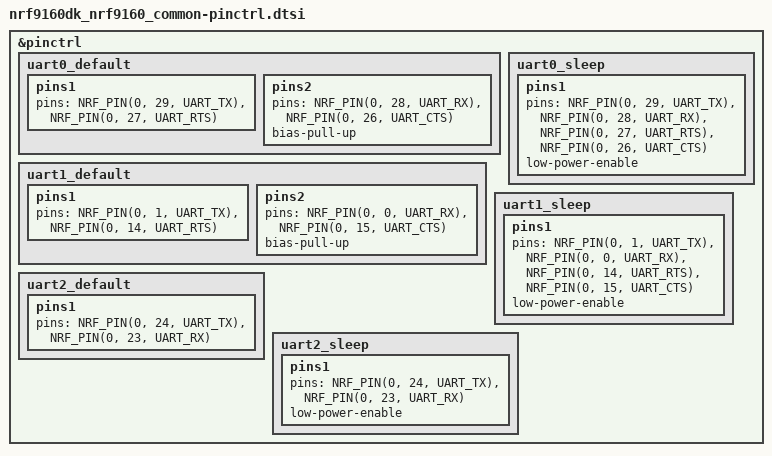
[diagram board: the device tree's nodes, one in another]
/*
 * Copyright (c) 2021 Nordic Semiconductor ASA
 * SPDX-License-Identifier: Apache-2.0
 */

&pinctrl {
	uart0_default: uart0_default {
		pins1 {
			pins = <NRF_PIN(0, 29, UART_TX)>,
			       <NRF_PIN(0, 27, UART_RTS)>;
		};
		pins2 {
			pins = <NRF_PIN(0, 28, UART_RX)>,
			       <NRF_PIN(0, 26, UART_CTS)>;
			bias-pull-up;
		};
	};

	uart0_sleep: uart0_sleep {
		pins1 {
			pins = <NRF_PIN(0, 29, UART_TX)>,
			       <NRF_PIN(0, 28, UART_RX)>,
			       <NRF_PIN(0, 27, UART_RTS)>,
			       <NRF_PIN(0, 26, UART_CTS)>;
			low-power-enable;
		};
	};

	uart1_default: uart1_default {
		pins1 {
			pins = <NRF_PIN(0, 1, UART_TX)>,
			       <NRF_PIN(0, 14, UART_RTS)>;
		};
		pins2 {
			pins = <NRF_PIN(0, 0, UART_RX)>,
			       <NRF_PIN(0, 15, UART_CTS)>;
			bias-pull-up;
		};
	};

	uart1_sleep: uart1_sleep {
		pins1 {
			pins = <NRF_PIN(0, 1, UART_TX)>,
			       <NRF_PIN(0, 0, UART_RX)>,
			       <NRF_PIN(0, 14, UART_RTS)>,
			       <NRF_PIN(0, 15, UART_CTS)>;
			low-power-enable;
		};
	};

	uart2_default: uart2_default {
		pins1 {
			pins = <NRF_PIN(0, 24, UART_TX)>,
			       <NRF_PIN(0, 23, UART_RX)>;
		};
	};

	uart2_sleep: uart2_sleep {
		pins1 {
			pins = <NRF_PIN(0, 24, UART_TX)>,
			       <NRF_PIN(0, 23, UART_RX)>;
			low-power-enable;
		};
	};

};
